VERSION "WUFR 23.1.0"

NS_ :

BS_: 250000 : 0,0

BU_: DAQ PE3

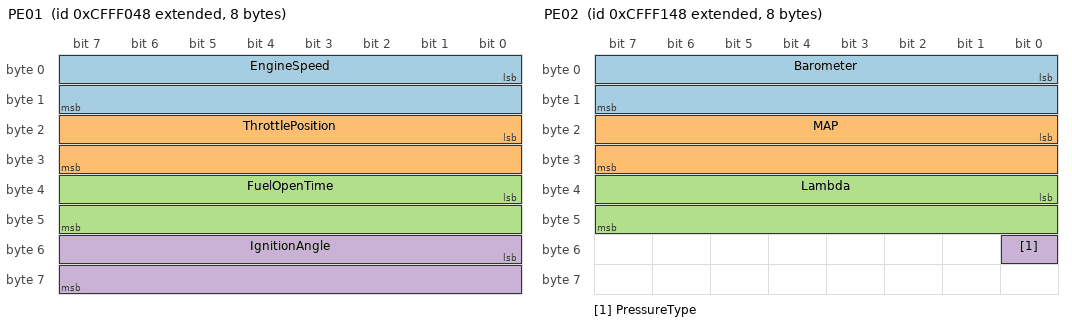
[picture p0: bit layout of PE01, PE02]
BO_ 2365583432 PE01: 8 PE3
 SG_ EngineSpeed : 0|16@1+ (1,0) [0|30000] "rpm"  DAQ
 SG_ ThrottlePosition : 16|16@1- (0.1,0) [0|100] "%"  DAQ
 SG_ FuelOpenTime : 32|16@1- (0.1,0) [0|30] "ms"  DAQ
 SG_ IgnitionAngle : 48|16@1- (0.1,0) [-20|100] "deg"  DAQ

BO_ 2365583688 PE02: 8 PE3
 SG_ Barometer : 0|16@1- (0.01,0) [0|300] "kPa"  DAQ
 SG_ MAP : 16|16@1- (0.01,0) [0|300] "kPa"  DAQ
 SG_ Lambda : 32|16@1- (0.01,0) [0|10] "lambda"  DAQ
 SG_ PressureType : 48|1@1+ (1,0) [0|1] "0-psi,1-kPa"  DAQ

BO_ 2365583944 PE03: 8 PE3
 SG_ O2Cond :48|16@1- (0.0001621,.499) [0|5] "lambda"  DAQ
 SG_ AnalogInput2 : 16|16@1- (0.001,0) [0|5] "volts"  DAQ
 SG_ FuelPressure : 32|16@1- (0.025,-12.5) [0|100] "psi"  DAQ
 SG_ GearPosition : 48|16@1- (0.001414,-0.0425) [0|6] "gear"  DAQ

BO_ 2365584200 PE04: 8 PE3
 SG_ AnalogInput5 : 0|16@1- (0.001,.0) [0|5] "volts"  DAQ
 SG_ OilPressure : 16|16@1- (0.025,-12.5) [0|5] "psi"  DAQ
 SG_ AnalogInput7 : 32|16@1- (0.001,0) [0|5] "volts"  DAQ
 SG_ AnalogInput8 : 16|16@1- (0.001,0) [0|5] "volts"  DAQ

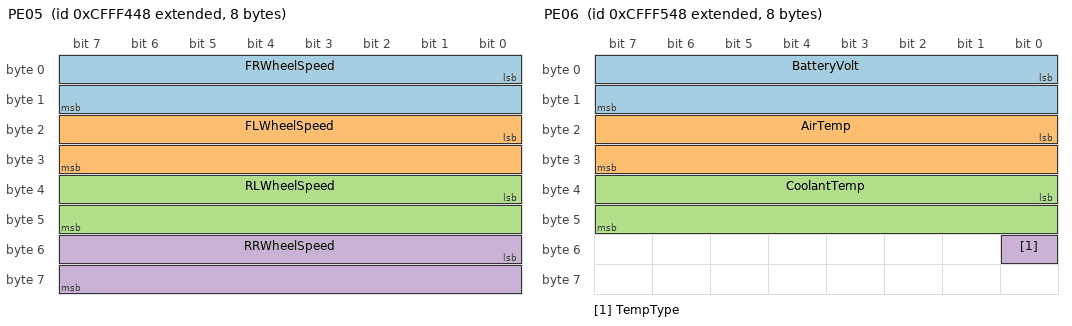
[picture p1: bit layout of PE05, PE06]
BO_ 2365584456 PE05: 8 PE3
 SG_ FRWheelSpeed : 0|16@1- (0.2008,0) [0|120] "mph"  DAQ
 SG_ FLWheelSpeed: 16|16@1- (0.2008,0) [0|120] "mph"  DAQ
 SG_ RLWheelSpeed : 32|16@1- (0.2008,0) [0|120] "mph"  DAQ
 SG_ RRWheelSpeed : 48|16@1- (0.2008,0) [0|120] "mph"  DAQ

BO_ 2365584712 PE06: 8 PE3
 SG_ BatteryVolt : 0|16@1- (0.01,0) [0|22] "volts"  DAQ
 SG_ AirTemp : 16|16@1- (0.1,0) [-1000|1000] "F"  DAQ
 SG_ CoolantTemp : 32|16@1- (0.1,0) [-1000|1000] "F"  DAQ
 SG_ TempType : 48|1@1+ (1,0) [0|1] "0-F,1-C"  DAQ

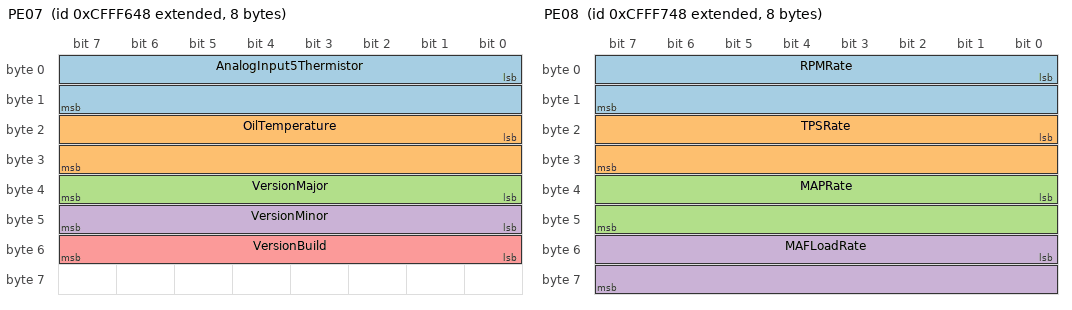
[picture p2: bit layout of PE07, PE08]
BO_ 2365584968 PE07: 8 PE3
 SG_ AnalogInput5Thermistor : 0|16@1- (0.1,0) [-1000|1000] "F"  DAQ
 SG_ OilTemperature : 16|16@1- (0.1,0) [-1000|1000] "F"  DAQ
 SG_ VersionMajor : 32|8@1+ (1,0) [0|255] ""  DAQ
 SG_ VersionMinor : 40|8@1+ (1,0) [0|255] ""  DAQ
 SG_ VersionBuild : 48|8@1+ (1,0) [0|255] ""  DAQ

BO_ 2365585224 PE08: 8 PE3
 SG_ RPMRate : 0|16@1- (1,0) [-10000|10000] "rpm/sec"  DAQ
 SG_ TPSRate : 16|16@1- (1,0) [-3000|3000] "%/sec"  DAQ
 SG_ MAPRate : 32|16@1- (1,0) [-3000|3000] "psi/sec"  DAQ
 SG_ MAFLoadRate : 48|16@1- (0.1,0) [-300|300] "g/rev/sec"  DAQ

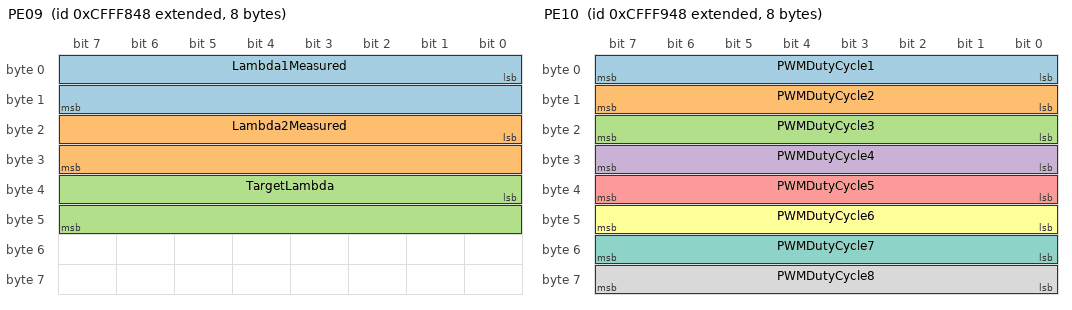
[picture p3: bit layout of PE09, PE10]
BO_ 2365585480 PE09: 8 PE3
 SG_ Lambda1Measured : 0|16@1- (0.01,0) [0|10] "lambda"  DAQ
 SG_ Lambda2Measured : 16|16@1- (0.01,0) [0|10] "lambda"  DAQ
 SG_ TargetLambda : 32|16@1- (0.01,0) [0|2.5] "lambda"  DAQ

BO_ 2365585736 PE10: 8 PE3
 SG_ PWMDutyCycle1 : 0|8@1+ (0.5,0) [0|100] "%"  DAQ
 SG_ PWMDutyCycle2 : 8|8@1+ (0.5,0) [0|100] "%"  DAQ
 SG_ PWMDutyCycle3 : 16|8@1+ (0.5,0) [0|100] "%"  DAQ
 SG_ PWMDutyCycle4 : 24|8@1+ (0.5,0) [0|100] "%"  DAQ
 SG_ PWMDutyCycle5 : 32|8@1+ (0.5,0) [0|100] "%"  DAQ
 SG_ PWMDutyCycle6 : 40|8@1+ (0.5,0) [0|100] "%"  DAQ
 SG_ PWMDutyCycle7 : 48|8@1+ (0.5,0) [0|100] "%"  DAQ
 SG_ PWMDutyCycle8 : 56|8@1+ (0.5,0) [0|100] "%"  DAQ

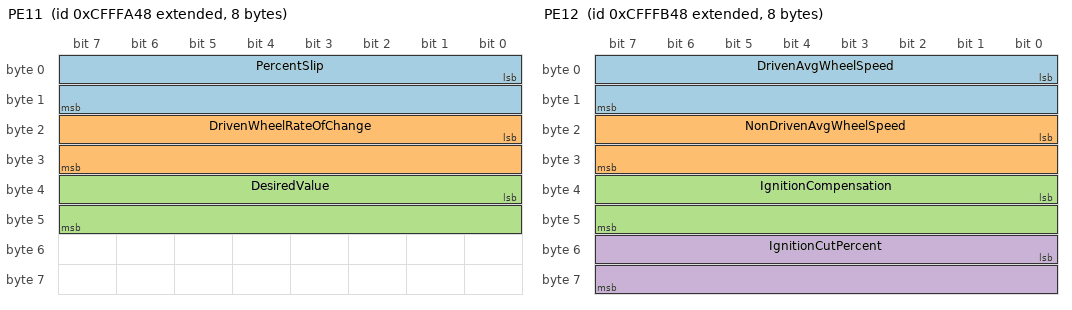
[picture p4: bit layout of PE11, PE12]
BO_ 2365585992 PE11: 8 PE3
 SG_ PercentSlip : 0|16@1- (0.1,0) [-3000|3000] "%"  DAQ
 SG_ DrivenWheelRateOfChange : 16|16@1- (0.1,0) [-3000|3000] "fs/sec/sec"  DAQ
 SG_ DesiredValue : 32|16@1- (0.1,0) [-3000|3000] "%"  DAQ

BO_ 2365586248 PE12: 8 PE3
 SG_ DrivenAvgWheelSpeed : 0|16@1+ (0.1,0) [0|3000] "ft/sec"  DAQ
 SG_ NonDrivenAvgWheelSpeed : 16|16@1+ (0.1,0) [0|3000] "ft/sec"  DAQ
 SG_ IgnitionCompensation : 32|16@1- (0.1,0) [0|100] "deg"  DAQ
 SG_ IgnitionCutPercent : 48|16@1- (0.1,0) [0|100] "%"  DAQ

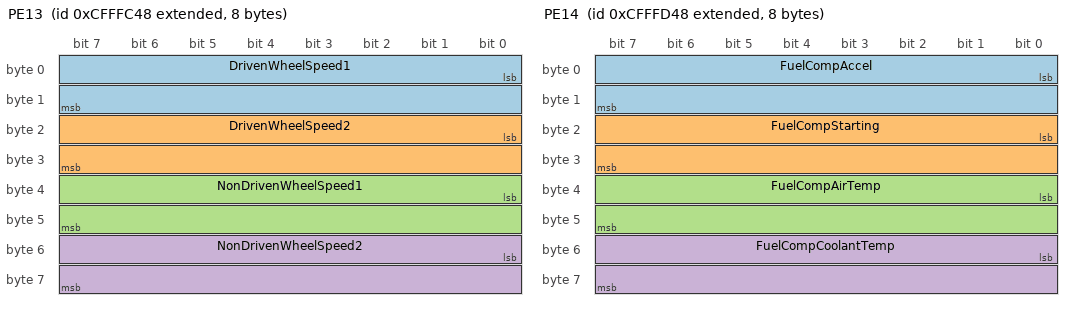
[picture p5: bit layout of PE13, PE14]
BO_ 2365586504 PE13: 8 PE3
 SG_ DrivenWheelSpeed1 : 0|16@1+ (0.1,0) [0|3000] "ft/sec"  DAQ
 SG_ DrivenWheelSpeed2 : 16|16@1+ (0.1,0) [0|3000] "ft/sec"  DAQ
 SG_ NonDrivenWheelSpeed1 : 32|16@1+ (0.1,0) [0|3000] "ft/sec"  DAQ
 SG_ NonDrivenWheelSpeed2 : 48|16@1+ (0.1,0) [0|3000] "ft/sec"  DAQ

BO_ 2365586760 PE14: 8 PE3
 SG_ FuelCompAccel : 0|16@1- (0.1,0) [0|500] "%"  DAQ
 SG_ FuelCompStarting : 16|16@1- (0.1,0) [0|500] "%"  DAQ
 SG_ FuelCompAirTemp : 32|16@1- (0.1,0) [0|500] "%"  DAQ
 SG_ FuelCompCoolantTemp : 48|16@1- (0.1,0) [0|500] "%"  DAQ

BO_ 2365587016 PE15: 8 PE3
 SG_ FuelCompBarometer : 0|16@1- (0.1,0) [0|500] "%"  DAQ
 SG_ FuelCompMAP : 16|16@1- (0.1,0) [0|500] "%"  DAQ

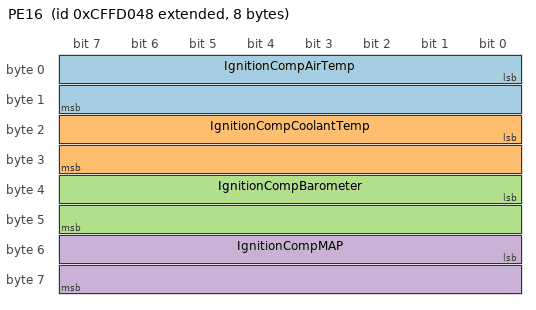
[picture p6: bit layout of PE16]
BO_ 2365575240 PE16: 8 PE3
 SG_ IgnitionCompAirTemp : 0|16@1- (0.1,0) [-20|20] "deg"  DAQ
 SG_ IgnitionCompCoolantTemp : 16|16@1- (0.1,0) [-20|20] "deg"  DAQ
 SG_ IgnitionCompBarometer : 32|16@1- (0.1,0) [-20|20] "deg"  DAQ
 SG_ IgnitionCompMAP : 48|16@1- (0.1,0) [-20|20] "deg"  DAQ

CM_ BU_ DAQ "Dashboard Datalogger and Telemetry";
CM_ BU_ PE3 "Engine control unit";
BA_DEF_  "BusType" STRING ;
BA_DEF_ BO_  "GenMsgSendType" ENUM  "Cyclic";
BA_DEF_ BO_  "GenMsgCycleTime" INT 1 10000;
BA_DEF_DEF_  "BusType" "CAN";
BA_DEF_DEF_  "GenMsgSendType" "Cyclic";
BA_DEF_DEF_  "GenMsgCycleTime" 100;
BA_ "GenMsgCycleTime" BO_ 2365583432 50;
BA_ "GenMsgCycleTime" BO_ 2365583688 50;
BA_ "GenMsgCycleTime" BO_ 2365584712 1000;
BA_ "GenMsgCycleTime" BO_ 2365584968 1000;
